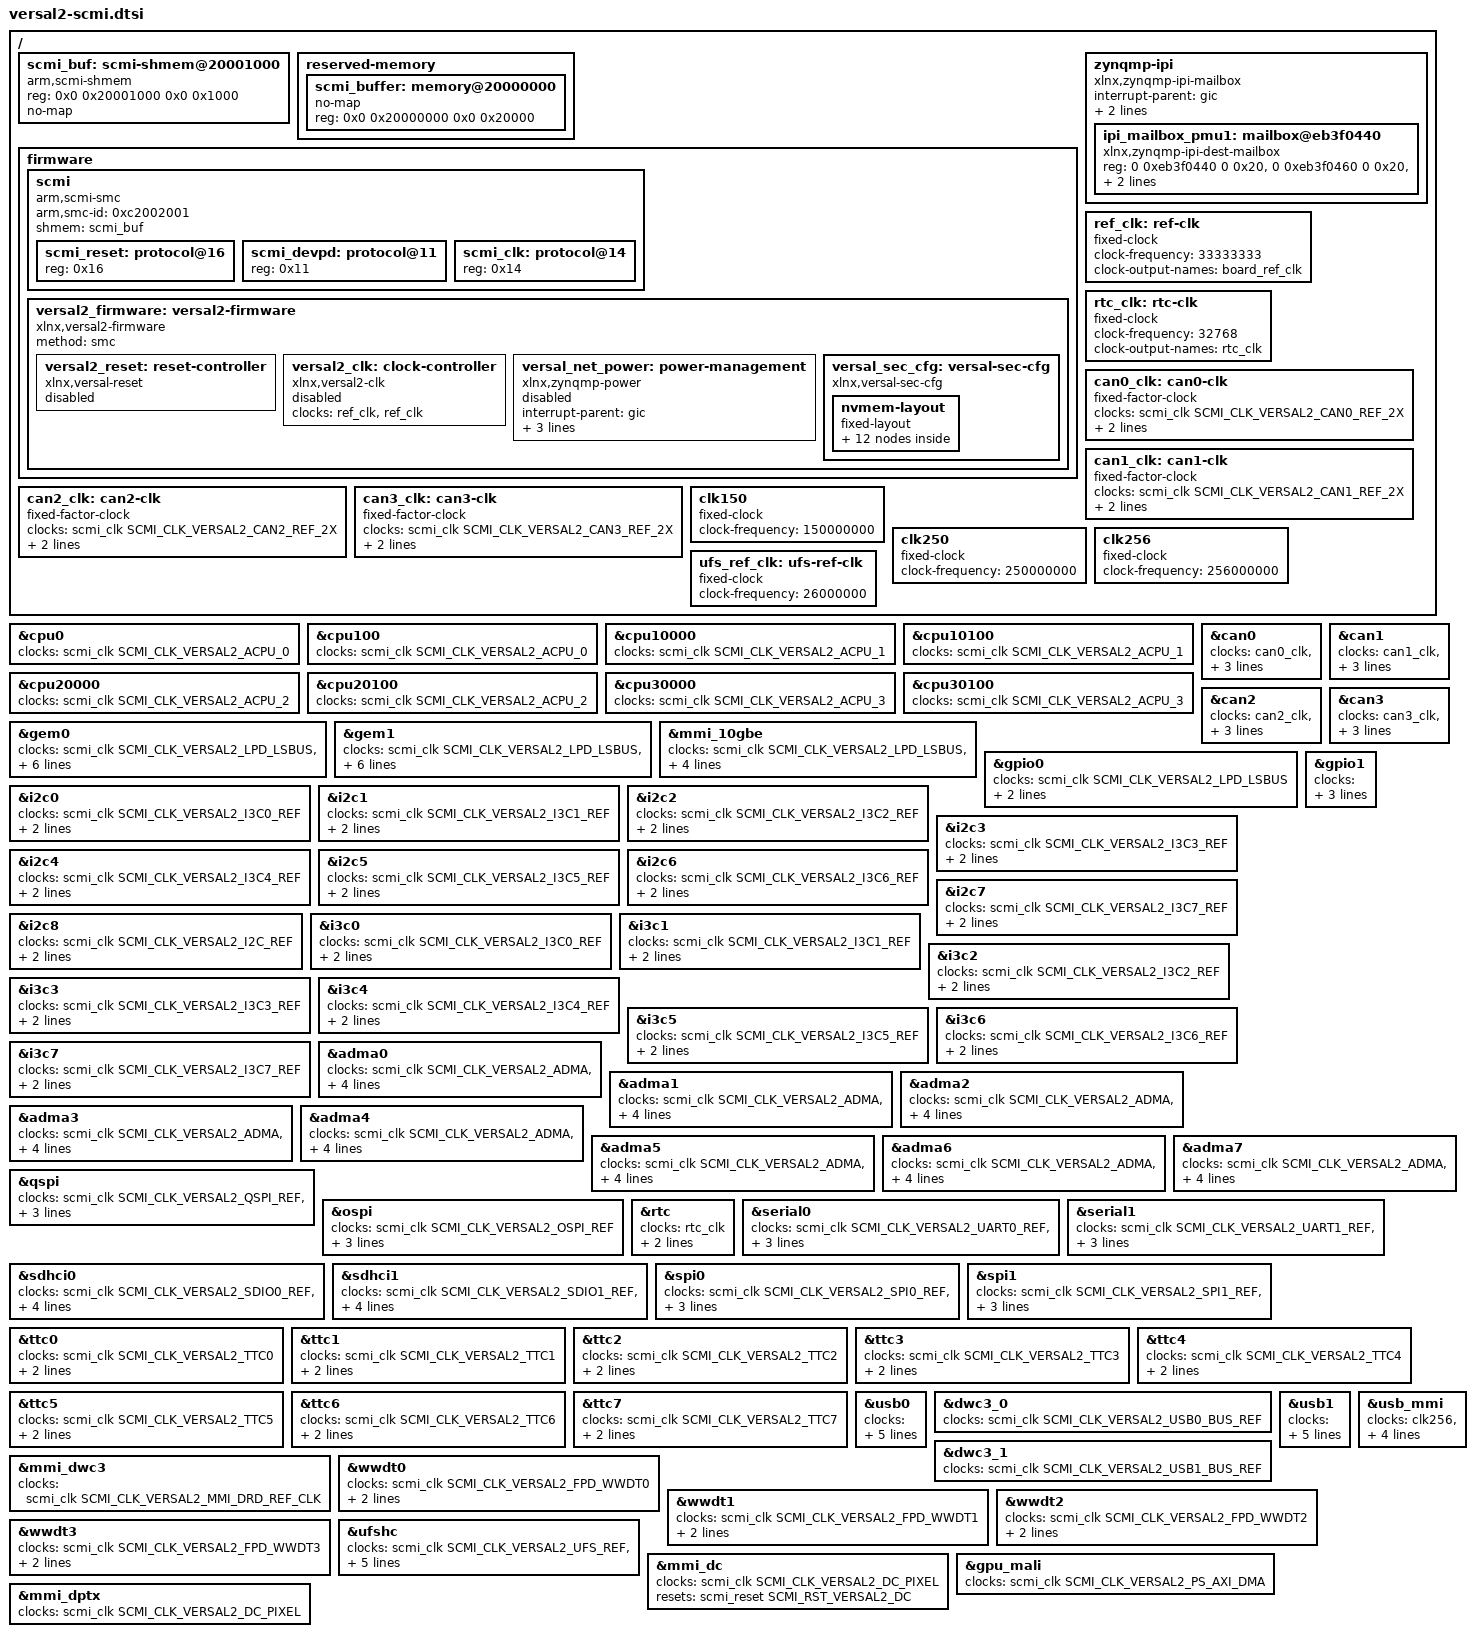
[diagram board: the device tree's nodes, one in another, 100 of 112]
// SPDX-License-Identifier: GPL-2.0
/*
 * DTS file for AMD Versal2 with SCMI
 *
 * Copyright (C) 2026, Advanced Micro Devices, Inc.
 */

#include "versal2-scmi-clk.h"
#include "versal2-scmi-power.h"
#include "versal2-scmi-reset.h"

/ {
	#address-cells = <2>;
	#size-cells = <2>;

	/* SCMI shared memory carve-out, shared with TF-A and Linux */
	scmi_buf: scmi-shmem@20001000 {
		compatible = "arm,scmi-shmem";
		reg = <0x0 0x20001000 0x0 0x1000>;
		no-map;
	};

	reserved-memory {
		#address-cells = <2>;
		#size-cells = <2>;

		scmi_buffer: memory@20000000 {
			no-map;
			reg = <0x0 0x20000000 0x0 0x20000>;
		};
	};

	firmware {
		scmi: scmi { /* Should be injected by firmware */
			compatible = "arm,scmi-smc";
			arm,smc-id = <0xc2002001>;
			#address-cells = <1>;
			#size-cells = <0>;
			shmem = <&scmi_buf>;

			/* Ensures the SCMI agent is probed before reloc and the serial device */
			bootph-all;

			scmi_reset: protocol@16 {
				reg = <0x16>;
				#reset-cells = <1>;
			};

			scmi_devpd: protocol@11 {
				reg = <0x11>;
				#power-domain-cells = <1>;
			};

			scmi_clk: protocol@14 {
				reg = <0x14>;
				#clock-cells = <1>;
			};
		};

		versal2_firmware: versal2-firmware {
			compatible = "xlnx,versal2-firmware";
			bootph-all;
			method = "smc";
			#power-domain-cells = <1>;

			versal2_reset: reset-controller {
				compatible = "xlnx,versal-reset";
				status = "disabled";
				#reset-cells = <1>;
			};

			versal2_clk: clock-controller {
				#clock-cells = <1>;
				status = "disabled";
				compatible = "xlnx,versal2-clk";
				bootph-all;
				clocks = <&ref_clk>, <&ref_clk>;
				clock-names = "ref", "pl_alt_ref";
			};

			versal_net_power: power-management {
				compatible = "xlnx,zynqmp-power";
				status = "disabled";
				interrupt-parent = <&gic>;
				interrupts = <0 57 4>;
				mboxes = <&ipi_mailbox_pmu1 0>,
					 <&ipi_mailbox_pmu1 1>;
				mbox-names = "tx", "rx";
			};

			versal_sec_cfg: versal-sec-cfg {
				compatible = "xlnx,versal-sec-cfg";
				nvmem-layout {
					compatible = "fixed-layout";
					#address-cells = <1>;
					#size-cells = <1>;

					bbram_zeroize: bbram-zeroize@4 {
						reg = <0x04 0x4>;
					};

					bbram_key: bbram-key@10 {
						reg = <0x10 0x20>;
					};

					bbram_usr: bbram-usr@30 {
						reg = <0x30 0x4>;
					};

					bbram_lock: bbram-lock@48 {
						reg = <0x48 0x4>;
					};

					user_key0: user-key@110 {
						reg = <0x110 0x20>;
					};

					user_key1: user-key@130 {
						reg = <0x130 0x20>;
					};

					user_key2: user-key@150 {
						reg = <0x150 0x20>;
					};

					user_key3: user-key@170 {
						reg = <0x170 0x20>;
					};

					user_key4: user-key@190 {
						reg = <0x190 0x20>;
					};

					user_key5: user-key@1b0 {
						reg = <0x1b0 0x20>;
					};

					user_key6: user-key@1d0 {
						reg = <0x1d0 0x20>;
					};

					user_key7: user-key@1f0 {
						reg = <0x1f0 0x20>;
					};
				};
			};
		};
	};

	zynqmp-ipi {
		compatible = "xlnx,zynqmp-ipi-mailbox";
		interrupt-parent = <&gic>;
		interrupts = <0 57 4>;
		xlnx,ipi-id = <2>;
		#address-cells = <2>;
		#size-cells = <2>;
		ranges;

		ipi_mailbox_pmu1: mailbox@eb3f0440 {
			compatible = "xlnx,zynqmp-ipi-dest-mailbox";
			reg = <0 0xeb3f0440 0 0x20>,
			      <0 0xeb3f0460 0 0x20>,
			      <0 0xeb3f0280 0 0x20>,
			      <0 0xeb3f02a0 0 0x20>;
			reg-names = "local_request_region", "local_response_region",
				    "remote_request_region", "remote_response_region";
			#mbox-cells = <1>;
			xlnx,ipi-id = <1>;
		};
	};

	ref_clk: ref-clk {
		bootph-all;
		compatible = "fixed-clock";
		#clock-cells = <0>;
		clock-frequency = <33333333>;
		clock-output-names = "board_ref_clk";
	};

	rtc_clk: rtc-clk {
		bootph-all;
		compatible = "fixed-clock";
		#clock-cells = <0>;
		clock-frequency = <32768>;
		clock-output-names = "rtc_clk";
	};

	can0_clk: can0-clk {
		#clock-cells = <0>;
		compatible = "fixed-factor-clock";
		clocks = <&scmi_clk SCMI_CLK_VERSAL2_CAN0_REF_2X>;
		clock-div = <2>;
		clock-mult = <1>;
	};

	can1_clk: can1-clk {
		#clock-cells = <0>;
		compatible = "fixed-factor-clock";
		clocks = <&scmi_clk SCMI_CLK_VERSAL2_CAN1_REF_2X>;
		clock-div = <2>;
		clock-mult = <1>;
	};

	can2_clk: can2-clk {
		#clock-cells = <0>;
		compatible = "fixed-factor-clock";
		clocks = <&scmi_clk SCMI_CLK_VERSAL2_CAN2_REF_2X>;
		clock-div = <2>;
		clock-mult = <1>;
	};

	can3_clk: can3-clk {
		#clock-cells = <0>;
		compatible = "fixed-factor-clock";
		clocks = <&scmi_clk SCMI_CLK_VERSAL2_CAN3_REF_2X>;
		clock-div = <2>;
		clock-mult = <1>;
	};

	clk150: clk150 {
		compatible = "fixed-clock";
		#clock-cells = <0>;
		clock-frequency = <150000000>;
	};

	clk250: clk250 {
		compatible = "fixed-clock";
		#clock-cells = <0>;
		clock-frequency = <250000000>;
	};

	clk256: clk256 {
		compatible = "fixed-clock";
		#clock-cells = <0>;
		clock-frequency = <256000000>;
	};

	ufs_ref_clk: ufs-ref-clk {
		compatible = "fixed-clock";
		#clock-cells = <0>;
		/* Override in board dts if different from default 26 MHz */
		clock-frequency = <26000000>;
	};
};

&cpu0 {
	clocks = <&scmi_clk SCMI_CLK_VERSAL2_ACPU_0>;
	/delete-property/ operating-points-v2;
};

&cpu100 {
	clocks = <&scmi_clk SCMI_CLK_VERSAL2_ACPU_0>;
	/delete-property/ operating-points-v2;
};

&cpu10000 {
	clocks = <&scmi_clk SCMI_CLK_VERSAL2_ACPU_1>;
	/delete-property/ operating-points-v2;
};

&cpu10100 {
	clocks = <&scmi_clk SCMI_CLK_VERSAL2_ACPU_1>;
	/delete-property/ operating-points-v2;
};

&cpu20000 {
	clocks = <&scmi_clk SCMI_CLK_VERSAL2_ACPU_2>;
	/delete-property/ operating-points-v2;
};

&cpu20100 {
	clocks = <&scmi_clk SCMI_CLK_VERSAL2_ACPU_2>;
	/delete-property/ operating-points-v2;
};

&cpu30000 {
	clocks = <&scmi_clk SCMI_CLK_VERSAL2_ACPU_3>;
	/delete-property/ operating-points-v2;
};

&cpu30100 {
	clocks = <&scmi_clk SCMI_CLK_VERSAL2_ACPU_3>;
	/delete-property/ operating-points-v2;
};

&can0 {
	clocks = <&can0_clk>, <&scmi_clk SCMI_CLK_VERSAL2_LPD_LSBUS>;
	power-domains = <&scmi_devpd SCMI_PD_VERSAL2_DEV_CAN_FD_0>;
};

&can1 {
	clocks = <&can1_clk>, <&scmi_clk SCMI_CLK_VERSAL2_LPD_LSBUS>;
	power-domains = <&scmi_devpd SCMI_PD_VERSAL2_DEV_CAN_FD_1>;
};

&can2 {
	clocks = <&can2_clk>, <&scmi_clk SCMI_CLK_VERSAL2_LPD_LSBUS>;
	power-domains = <&scmi_devpd SCMI_PD_VERSAL2_DEV_CAN_FD_2>;
};

&can3 {
	clocks = <&can3_clk>, <&scmi_clk SCMI_CLK_VERSAL2_LPD_LSBUS>;
	power-domains = <&scmi_devpd SCMI_PD_VERSAL2_DEV_CAN_FD_3>;
};

&gem0 {
	clocks = <&scmi_clk SCMI_CLK_VERSAL2_LPD_LSBUS>,
		 <&scmi_clk SCMI_CLK_VERSAL2_GEM0_REF>, <&scmi_clk SCMI_CLK_VERSAL2_GEM0_TX>,
		 <&scmi_clk SCMI_CLK_VERSAL2_GEM0_RX>, <&scmi_clk SCMI_CLK_VERSAL2_GEM_TSU>;
	power-domains = <&scmi_devpd SCMI_PD_VERSAL2_DEV_GEM_0>;
};

&gem1 {
	clocks = <&scmi_clk SCMI_CLK_VERSAL2_LPD_LSBUS>,
		 <&scmi_clk SCMI_CLK_VERSAL2_GEM1_REF>, <&scmi_clk SCMI_CLK_VERSAL2_GEM1_TX>,
		 <&scmi_clk SCMI_CLK_VERSAL2_GEM1_RX>, <&scmi_clk SCMI_CLK_VERSAL2_GEM_TSU>;
	power-domains = <&scmi_devpd SCMI_PD_VERSAL2_DEV_GEM_1>;
};

&mmi_10gbe {
	clocks = <&scmi_clk SCMI_CLK_VERSAL2_LPD_LSBUS>,
		 <&scmi_clk SCMI_CLK_VERSAL2_MMI_GEM_HCLK>, <&clk150>,
		 <&clk250>;
	power-domains = <&scmi_devpd SCMI_PD_VERSAL2_DEV_MMI_GEM>;
};

&gpio0 {
	clocks = <&scmi_clk SCMI_CLK_VERSAL2_LPD_LSBUS>;
	power-domains = <&scmi_devpd SCMI_PD_VERSAL2_DEV_GPIO>;
};

&gpio1 {
	clocks = <&scmi_clk SCMI_CLK_VERSAL2_PMC_LSBUS_REF>;
	power-domains = <&scmi_devpd SCMI_PD_VERSAL2_DEV_GPIO_PMC>;
};

&i2c0 {
	clocks = <&scmi_clk SCMI_CLK_VERSAL2_I3C0_REF>;
	power-domains = <&scmi_devpd SCMI_PD_VERSAL2_DEV_I2C_0>;
};

&i2c1 {
	clocks = <&scmi_clk SCMI_CLK_VERSAL2_I3C1_REF>;
	power-domains = <&scmi_devpd SCMI_PD_VERSAL2_DEV_I2C_1>;
};

&i2c2 {
	clocks = <&scmi_clk SCMI_CLK_VERSAL2_I3C2_REF>;
	power-domains = <&scmi_devpd SCMI_PD_VERSAL2_DEV_I2C_2>;
};

&i2c3 {
	clocks = <&scmi_clk SCMI_CLK_VERSAL2_I3C3_REF>;
	power-domains = <&scmi_devpd SCMI_PD_VERSAL2_DEV_I2C_3>;
};

&i2c4 {
	clocks = <&scmi_clk SCMI_CLK_VERSAL2_I3C4_REF>;
	power-domains = <&scmi_devpd SCMI_PD_VERSAL2_DEV_I2C_4>;
};

&i2c5 {
	clocks = <&scmi_clk SCMI_CLK_VERSAL2_I3C5_REF>;
	power-domains = <&scmi_devpd SCMI_PD_VERSAL2_DEV_I2C_5>;
};

&i2c6 {
	clocks = <&scmi_clk SCMI_CLK_VERSAL2_I3C6_REF>;
	power-domains = <&scmi_devpd SCMI_PD_VERSAL2_DEV_I2C_6>;
};

&i2c7 {
	clocks = <&scmi_clk SCMI_CLK_VERSAL2_I3C7_REF>;
	power-domains = <&scmi_devpd SCMI_PD_VERSAL2_DEV_I2C_7>;
};

&i2c8 {
	clocks = <&scmi_clk SCMI_CLK_VERSAL2_I2C_REF>;
	power-domains = <&scmi_devpd SCMI_PD_VERSAL2_DEV_I2C_PMC>;
};

&i3c0 {
	clocks = <&scmi_clk SCMI_CLK_VERSAL2_I3C0_REF>;
	power-domains = <&scmi_devpd SCMI_PD_VERSAL2_DEV_I2C_0>;
};

&i3c1 {
	clocks = <&scmi_clk SCMI_CLK_VERSAL2_I3C1_REF>;
	power-domains = <&scmi_devpd SCMI_PD_VERSAL2_DEV_I2C_1>;
};

&i3c2 {
	clocks = <&scmi_clk SCMI_CLK_VERSAL2_I3C2_REF>;
	power-domains = <&scmi_devpd SCMI_PD_VERSAL2_DEV_I2C_2>;
};

&i3c3 {
	clocks = <&scmi_clk SCMI_CLK_VERSAL2_I3C3_REF>;
	power-domains = <&scmi_devpd SCMI_PD_VERSAL2_DEV_I2C_3>;
};

&i3c4 {
	clocks = <&scmi_clk SCMI_CLK_VERSAL2_I3C4_REF>;
	power-domains = <&scmi_devpd SCMI_PD_VERSAL2_DEV_I2C_4>;
};

&i3c5 {
	clocks = <&scmi_clk SCMI_CLK_VERSAL2_I3C5_REF>;
	power-domains = <&scmi_devpd SCMI_PD_VERSAL2_DEV_I2C_5>;
};

&i3c6 {
	clocks = <&scmi_clk SCMI_CLK_VERSAL2_I3C6_REF>;
	power-domains = <&scmi_devpd SCMI_PD_VERSAL2_DEV_I2C_6>;
};

&i3c7 {
	clocks = <&scmi_clk SCMI_CLK_VERSAL2_I3C7_REF>;
	power-domains = <&scmi_devpd SCMI_PD_VERSAL2_DEV_I2C_7>;
};

&adma0 {
	clocks = <&scmi_clk SCMI_CLK_VERSAL2_ADMA>, <&scmi_clk SCMI_CLK_VERSAL2_LPD_LSBUS>;
	power-domains = <&scmi_devpd SCMI_PD_VERSAL2_DEV_ADMA_0>;
	resets = <&scmi_reset SCMI_RST_VERSAL2_ADMA_0>;
};

&adma1 {
	clocks = <&scmi_clk SCMI_CLK_VERSAL2_ADMA>, <&scmi_clk SCMI_CLK_VERSAL2_LPD_LSBUS>;
	power-domains = <&scmi_devpd SCMI_PD_VERSAL2_DEV_ADMA_1>;
	resets = <&scmi_reset SCMI_RST_VERSAL2_ADMA_1>;
};

&adma2 {
	clocks = <&scmi_clk SCMI_CLK_VERSAL2_ADMA>, <&scmi_clk SCMI_CLK_VERSAL2_LPD_LSBUS>;
	power-domains = <&scmi_devpd SCMI_PD_VERSAL2_DEV_ADMA_2>;
	resets = <&scmi_reset SCMI_RST_VERSAL2_ADMA_2>;
};

&adma3 {
	clocks = <&scmi_clk SCMI_CLK_VERSAL2_ADMA>, <&scmi_clk SCMI_CLK_VERSAL2_LPD_LSBUS>;
	power-domains = <&scmi_devpd SCMI_PD_VERSAL2_DEV_ADMA_3>;
	resets = <&scmi_reset SCMI_RST_VERSAL2_ADMA_3>;
};

&adma4 {
	clocks = <&scmi_clk SCMI_CLK_VERSAL2_ADMA>, <&scmi_clk SCMI_CLK_VERSAL2_LPD_LSBUS>;
	power-domains = <&scmi_devpd SCMI_PD_VERSAL2_DEV_ADMA_4>;
	resets = <&scmi_reset SCMI_RST_VERSAL2_ADMA_4>;
};

&adma5 {
	clocks = <&scmi_clk SCMI_CLK_VERSAL2_ADMA>, <&scmi_clk SCMI_CLK_VERSAL2_LPD_LSBUS>;
	power-domains = <&scmi_devpd SCMI_PD_VERSAL2_DEV_ADMA_5>;
	resets = <&scmi_reset SCMI_RST_VERSAL2_ADMA_5>;
};

&adma6 {
	clocks = <&scmi_clk SCMI_CLK_VERSAL2_ADMA>, <&scmi_clk SCMI_CLK_VERSAL2_LPD_LSBUS>;
	power-domains = <&scmi_devpd SCMI_PD_VERSAL2_DEV_ADMA_6>;
	resets = <&scmi_reset SCMI_RST_VERSAL2_ADMA_6>;
};

&adma7 {
	clocks = <&scmi_clk SCMI_CLK_VERSAL2_ADMA>, <&scmi_clk SCMI_CLK_VERSAL2_LPD_LSBUS>;
	power-domains = <&scmi_devpd SCMI_PD_VERSAL2_DEV_ADMA_7>;
	resets = <&scmi_reset SCMI_RST_VERSAL2_ADMA_7>;
};

&qspi {
	clocks = <&scmi_clk SCMI_CLK_VERSAL2_QSPI_REF>, <&scmi_clk SCMI_CLK_VERSAL2_LPD_LSBUS>;
	power-domains = <&scmi_devpd SCMI_PD_VERSAL2_DEV_QSPI>;
};

&ospi {
	clocks = <&scmi_clk SCMI_CLK_VERSAL2_OSPI_REF>;
	power-domains = <&scmi_devpd SCMI_PD_VERSAL2_DEV_OSPI>;
	resets = <&scmi_reset SCMI_RST_VERSAL2_OSPI>;
};

&rtc {
	clocks = <&rtc_clk>;
	clock-names = "rtc";
	power-domains = <&scmi_devpd SCMI_PD_VERSAL2_DEV_RTC>;
};

&serial0 {
	clocks = <&scmi_clk SCMI_CLK_VERSAL2_UART0_REF>, <&scmi_clk SCMI_CLK_VERSAL2_LPD_LSBUS>;
	power-domains = <&scmi_devpd SCMI_PD_VERSAL2_DEV_UART_0>;
};

&serial1 {
	clocks = <&scmi_clk SCMI_CLK_VERSAL2_UART1_REF>, <&scmi_clk SCMI_CLK_VERSAL2_LPD_LSBUS>;
	power-domains = <&scmi_devpd SCMI_PD_VERSAL2_DEV_UART_1>;
};

&sdhci0 {
	clocks = <&scmi_clk SCMI_CLK_VERSAL2_SDIO0_REF>, <&scmi_clk SCMI_CLK_VERSAL2_LPD_LSBUS>,
		 <&scmi_clk SCMI_CLK_VERSAL2_SD_DLL_REF>;
	power-domains = <&scmi_devpd SCMI_PD_VERSAL2_DEV_SDIO_0>;
};

&sdhci1 {
	clocks = <&scmi_clk SCMI_CLK_VERSAL2_SDIO1_REF>, <&scmi_clk SCMI_CLK_VERSAL2_LPD_LSBUS>,
		 <&scmi_clk SCMI_CLK_VERSAL2_SD_DLL_REF>;
	power-domains = <&scmi_devpd SCMI_PD_VERSAL2_DEV_SDIO_1>;
};

&spi0 {
	clocks = <&scmi_clk SCMI_CLK_VERSAL2_SPI0_REF>, <&scmi_clk SCMI_CLK_VERSAL2_LPD_LSBUS>;
	power-domains = <&scmi_devpd SCMI_PD_VERSAL2_DEV_SPI_0>;
};

&spi1 {
	clocks = <&scmi_clk SCMI_CLK_VERSAL2_SPI1_REF>, <&scmi_clk SCMI_CLK_VERSAL2_LPD_LSBUS>;
	power-domains = <&scmi_devpd SCMI_PD_VERSAL2_DEV_SPI_1>;
};

&ttc0 {
	clocks = <&scmi_clk SCMI_CLK_VERSAL2_TTC0>;
	power-domains = <&scmi_devpd SCMI_PD_VERSAL2_DEV_TTC_0>;
};

&ttc1 {
	clocks = <&scmi_clk SCMI_CLK_VERSAL2_TTC1>;
	power-domains = <&scmi_devpd SCMI_PD_VERSAL2_DEV_TTC_1>;
};

&ttc2 {
	clocks = <&scmi_clk SCMI_CLK_VERSAL2_TTC2>;
	power-domains = <&scmi_devpd SCMI_PD_VERSAL2_DEV_TTC_2>;
};

&ttc3 {
	clocks = <&scmi_clk SCMI_CLK_VERSAL2_TTC3>;
	power-domains = <&scmi_devpd SCMI_PD_VERSAL2_DEV_TTC_3>;
};

&ttc4 {
	clocks = <&scmi_clk SCMI_CLK_VERSAL2_TTC4>;
	power-domains = <&scmi_devpd SCMI_PD_VERSAL2_DEV_TTC_4>;
};

&ttc5 {
	clocks = <&scmi_clk SCMI_CLK_VERSAL2_TTC5>;
	power-domains = <&scmi_devpd SCMI_PD_VERSAL2_DEV_TTC_5>;
};

&ttc6 {
	clocks = <&scmi_clk SCMI_CLK_VERSAL2_TTC6>;
	power-domains = <&scmi_devpd SCMI_PD_VERSAL2_DEV_TTC_6>;
};

&ttc7 {
	clocks = <&scmi_clk SCMI_CLK_VERSAL2_TTC7>;
	power-domains = <&scmi_devpd SCMI_PD_VERSAL2_DEV_TTC_7>;
};

&usb0 {
	clocks = <&scmi_clk SCMI_CLK_VERSAL2_USB0_BUS_REF>, <&scmi_clk SCMI_CLK_VERSAL2_USB0_BUS_REF>;
	power-domains = <&scmi_devpd SCMI_PD_VERSAL2_DEV_USB_0>;
	resets = <&scmi_reset SCMI_RST_VERSAL2_USB_0>;
};

&dwc3_0 {
	clocks = <&scmi_clk SCMI_CLK_VERSAL2_USB0_BUS_REF>;
};

&usb1 {
	clocks = <&scmi_clk SCMI_CLK_VERSAL2_USB1_BUS_REF>, <&scmi_clk SCMI_CLK_VERSAL2_USB1_BUS_REF>;
	power-domains = <&scmi_devpd SCMI_PD_VERSAL2_DEV_USB_1>;
	resets = <&scmi_reset SCMI_RST_VERSAL2_USB_1>;
};

&dwc3_1 {
	clocks = <&scmi_clk SCMI_CLK_VERSAL2_USB1_BUS_REF>;
};

&usb_mmi {
	clocks = <&clk256>, <&scmi_clk SCMI_CLK_VERSAL2_MMI_DRD_REF_CLK>;
	resets = <&scmi_reset SCMI_RST_VERSAL2_UDH_DRD>;
	power-domains = <&scmi_devpd SCMI_PD_VERSAL2_DEV_MMI_USB_DRD>;
};

&mmi_dwc3 {
	clocks = <&scmi_clk SCMI_CLK_VERSAL2_MMI_DRD_REF_CLK>;
};

&wwdt0 {
	clocks = <&scmi_clk SCMI_CLK_VERSAL2_FPD_WWDT0>;
	power-domains = <&scmi_devpd SCMI_PD_VERSAL2_DEV_FPD_SWDT_0>;
};

&wwdt1 {
	clocks = <&scmi_clk SCMI_CLK_VERSAL2_FPD_WWDT1>;
	power-domains = <&scmi_devpd SCMI_PD_VERSAL2_DEV_FPD_SWDT_1>;
};

&wwdt2 {
	clocks = <&scmi_clk SCMI_CLK_VERSAL2_FPD_WWDT2>;
	power-domains = <&scmi_devpd SCMI_PD_VERSAL2_DEV_FPD_SWDT_2>;
};

&wwdt3 {
	clocks = <&scmi_clk SCMI_CLK_VERSAL2_FPD_WWDT3>;
	power-domains = <&scmi_devpd SCMI_PD_VERSAL2_DEV_FPD_SWDT_3>;
};

&ufshc {
	clocks = <&scmi_clk SCMI_CLK_VERSAL2_UFS_REF>, <&ufs_ref_clk>;
	power-domains = <&scmi_devpd SCMI_PD_VERSAL2_DEV_UFS>;
	resets = <&scmi_reset SCMI_RST_VERSAL2_UFS>, <&scmi_reset SCMI_RST_VERSAL2_UFS_PHY>;
};

&mmi_dc {
	clocks = <&scmi_clk SCMI_CLK_VERSAL2_DC_PIXEL>;
	resets = <&scmi_reset SCMI_RST_VERSAL2_DC>;
};

&gpu_mali {
	clocks = <&scmi_clk SCMI_CLK_VERSAL2_PS_AXI_DMA>;
};

&mmi_dptx {
	clock-names = "pixel_clk";
	clocks = <&scmi_clk SCMI_CLK_VERSAL2_DC_PIXEL>;
};
